# MCU_ADC0 register map
Vendor: Texas Instruments
Peripheral module from a debugger description file (folder am65x).
Registers are 32-bit, access per field, reset values left out (the file's numbers can be read two ways) unless marked. A register's access mark holds for its fields unless they carry their own. Offsets are as the file gives them; lines under a group give offsets from that group; [hi:lo] are bit positions; {n}, {i} and the like mark numbered series; 'fields as' and 'values as' point back to an identical list; <NAME> marks a mode.

## MCU_ADC0
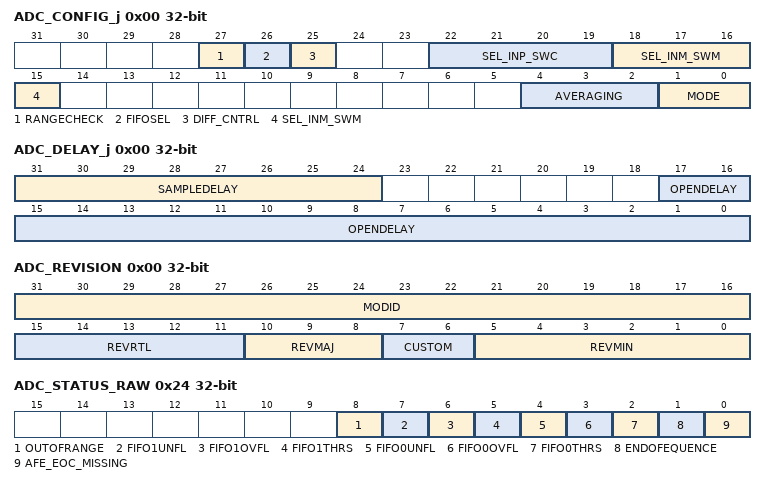
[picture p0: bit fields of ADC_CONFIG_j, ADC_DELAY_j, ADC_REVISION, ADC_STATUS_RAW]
0x00 ADC_CONFIG_j — The user should write to this register the values of the input pins send to the AFE during step 1. the StepConfig WriteEnable bit should be set to 1 before a write can occur. Offset = 64h + (j * 8h); where j = 0h to Fh
  [27] RANGECHECK rw — 0h = Disable ADC_RANGE check 1h = compare ADC data with ADC_RANGE
  [26] FIFOSEL rw — Sampled data will be stored in FIFO. 0h = FIFO0 1h = FIFO1
  [25] DIFF_CNTRL rw — DifferentialADC_CONTROL. 0h = Single ended 1h = Differential input
  [22:19] SEL_INP_SWC rw — SEL_INP pins SW configuration. 0h = Channel 1 1h = Channel 2 2h = Channel 3 3h = Channel 4 4h = Channel 5 5h = Channel 6 6h = Channel 7 7h = Channel 8 8h = VREFN
  [18:15] SEL_INM_SWM rw — SEL_INM pins negative differential. 0h = Channel 1 1h = Channel 2 2h = Channel 3 3h = Channel 4 4h = Channel 5 5h = Channel 6 6h = Channel 7 7h = Channel 8 8h = VREFN
  [4:2] AVERAGING rw — Number of samplings to average. 0h = no average 1h = 2 samples average 2h = 4 samples average 3h = 8 samples average 4h = 16 samples average
  [1:0] MODE rw — 0h = SW enabled, one-shot 1h = SW enabled, continuous 2h = HW synchronized, one-shot 3h = HW synchronized, continuous
0x00 ADC_DELAY_j — Controls number of clock periods to sample and delay. Offset = 68h + (j × 8h); where j = 0h to Fh
  [31:24] SAMPLEDELAY rw — This register will control the number of ADC clock cycles to hold SOC high. Any value programmed here will be added to the minimum requirement of 1 clock cycle.
  [17:0] OPENDELAY rw — Program the number of ADC clock cycles to wait after applying the step configuration registers and before sending the start of ADC conversion.
0x00 ADC_REVISION ro — IP Revision Identifier (X.Y.R) Used by software to track features, bugs, and compatibility.
  [31:16] MODID — Module ID field
  [15:11] REVRTL — RTLADC_REVISION. Will vary depending on release.
  [10:8] REVMAJ — Major
  [7:6] CUSTOM
  [5:0] REVMIN — Minor
0x20 ADC_EOI — The End of Interrupt () Register allows the CPU to acknowledge completion of an interrupt by writing to the for interrupt sources. An eoi_write signal will be generated and another interrupt will be triggered if interrupt sources remain. This register will be reset one cycle after it has been written to.
  [0] LINENUMEOI wo — Software End Of Interrupt (EOI) control.
0x24 ADC_STATUS_RAW — The register allows the MCU_ADC0/1 interrupt sources to be manually set when writing a 1 to a specific bit. Write 0: No action Write 1: Set event Read 0: No event pending Read 1: Event pending
  [8] OUTOFRANGE rw — Status raw for interrupt.
  [7] FIFO1UNFL rw — Status raw for interrupt.
  [6] FIFO1OVFL rw — Status raw for interrupt.
  [5] FIFO1THRS rw — Status raw for interrupt.
  [4] FIFO0UNFL rw — Status raw for interrupt.
  [3] FIFO0OVFL rw — Status raw for interrupt.
  [2] FIFO0THRS rw — Status raw for interrupt.
  [1] ENDOFEQUENCE rw — Status raw for interrupt.
  [0] AFE_EOC_MISSING rw — EOC from the analog front end missing at expected time after SOC.
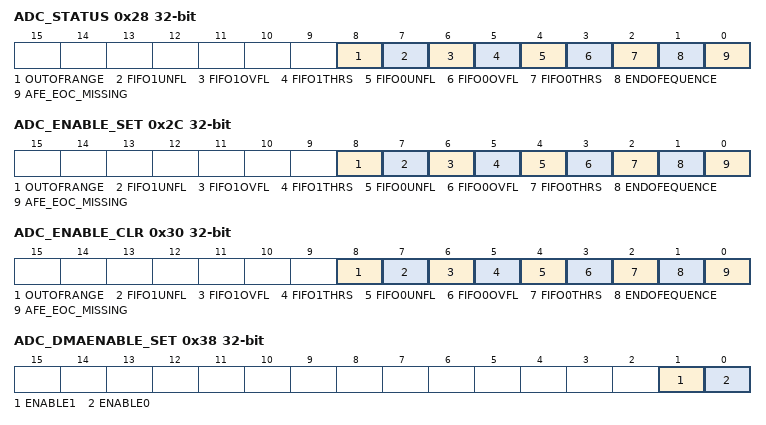
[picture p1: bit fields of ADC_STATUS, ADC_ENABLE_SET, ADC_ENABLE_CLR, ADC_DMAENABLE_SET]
0x28 ADC_STATUS — The register allows the MCU_ADC0/1 interrupt sources to be manually cleared when writing a 1 to a specific bit. Write 0: No action Write 1: Clear event Read 0: No event pending Read 1: Event pending
  [8] OUTOFRANGE rw — Enabled status for interrupt.
  [7] FIFO1UNFL rw — Enabled status for interrupt.
  [6] FIFO1OVFL rw — Enabled status for interrupt.
  [5] FIFO1THRS rw — Enabled status for interrupt.
  [4] FIFO0UNFL rw — Enabled status for interrupt.
  [3] FIFO0OVFL rw — Enabled status for interrupt.
  [2] FIFO0THRS rw — Enabled status for interrupt.
  [1] ENDOFEQUENCE rw — Enabled status for interrupt.
  [0] AFE_EOC_MISSING rw — EOC from the analog front end missing at expected time after SOC.
0x2C ADC_ENABLE_SET — The register allows the MCU_ADC0/1 interrupt sources to be manually enabled when writing a 1 to a specific bit. Write 0: No action Write 1: Enable event Read 0: Event is disabled Read 1: Event is enabled
  [8] OUTOFRANGE rw — Interrupt enable.
  [7] FIFO1UNFL rw — Interrupt enable.
  [6] FIFO1OVFL rw — Interrupt enable.
  [5] FIFO1THRS rw — Interrupt enable.
  [4] FIFO0UNFL rw — Interrupt enable.
  [3] FIFO0OVFL rw — Interrupt enable.
  [2] FIFO0THRS rw — Interrupt enable.
  [1] ENDOFEQUENCE rw — Interrupt enable.
  [0] AFE_EOC_MISSING rw — EOC from the analog front end missing at expected time after SOC
0x30 ADC_ENABLE_CLR — The register allows the MCU_ADC0/1 interrupt sources to be manually disabled when writing a 1 to a specific bit. Write 0: No action Write 1: Disable event Read 0: Event is disabled Read 1: Event is enabled
  [8] OUTOFRANGE rw — Interrupt disable.
  [7] FIFO1UNFL rw — Interrupt disable.
  [6] FIFO1OVFL rw — Interrupt disable.
  [5] FIFO1THRS rw — Interrupt disable.
  [4] FIFO0UNFL rw — Interrupt disable.
  [3] FIFO0OVFL rw — Interrupt disable.
  [2] FIFO0THRS rw — Interrupt disable.
  [1] ENDOFEQUENCE rw — Interrupt disable.
  [0] AFE_EOC_MISSING rw — EOC from the analog front end missing at expected time after SOC
0x38 ADC_DMAENABLE_SET — The register allows the enabling of DMA requests.
  [1] ENABLE1 rw — Enable DMA request FIFO1
  [0] ENABLE0 rw — Enable DMA request FIFO0
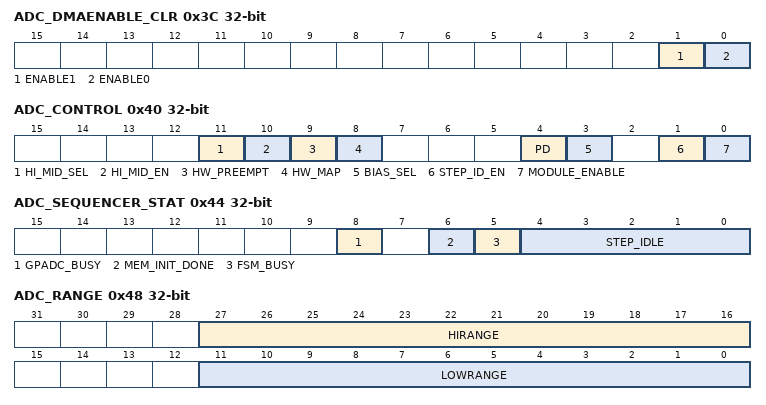
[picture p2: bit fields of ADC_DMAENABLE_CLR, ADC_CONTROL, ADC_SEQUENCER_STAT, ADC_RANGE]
0x3C ADC_DMAENABLE_CLR — The register allows the disabling of DMA requests.
  [1] ENABLE1 rw — Clears the enable of the DMA reguest FIFO1. Disable DMA request FIFO1 Write 0h = No action Write 1h = Disable DMA line Read 0h = DMA line disabled Read 1h = DMA line enabled
  [0] ENABLE0 rw — Clears the enable of the DMA reguest FIFO0. Disable DMA request FIFO0 Write 0h = No action Write 1h = Disable DMA line Read 0h = DMA line disabled Read 1h = DMA line enabled
0x40 ADC_CONTROL — Controls various parameters of the cotroller state.
  [11] HI_MID_SEL rw — Functional safety debug mode. 0h = Choose ADCREFP 1h = VMID reference input to ADC
  [10] HI_MID_EN rw — Functional safety debug mode. Enable fixed reference to ADC for testing.
  [9] HW_PREEMPT rw — 0h = SW steps are not preempted by HW events 1h = SW steps are preempted by HW events
  [8] HW_MAP rw — 0h = HW events are disabled 1h = HW events are enabled
  [4] PD rw — ADC Power Down control. 0h = AFE is powered up 1h = AFE is powered down (default) At default, AFE is powered down; Software must write 0 to turn on the power and wait 4 us before starting a conversion
  [3] BIAS_SEL rw — AFE select bias
  [1] STEP_ID_EN rw — Writing 1 to this bit will store the Step ID number with the captured ADC data in the FIFO. 0h = Write zeros 1h = Store the channel id tag
  [0] MODULE_ENABLE rw — ADC module enable bit. After programming all the configuration and step enable registers, write a 1 to this bit to start conversion. Writing a 0 will disable the module after the current conversion. Before turning on again, the ADC_SEQUENCER_STAT register show read back STEP_IDLE = 0h and FSM_BUSY = 0h. Enabling the controller will be held off until MEM_INIT_DONE = 1h.
0x44 ADC_SEQUENCER_STAT ro — SW can read this register to find out the currently scheduled step id being converted on the ADC port. If you want to turn the controller off and then back on, the step_id bit should be checked and compared to IDLE before enabling the ADC module again. Also, before enabling the controller again, the user should wait for the FSM bit 5 to read idl.
  [8] GPADC_BUSY — Monitor the AFE internal calibration (busy bit)
  [6] MEM_INIT_DONE — ADC_STATUS of RAM initialization. 1h = RAM initialization to 0 after reset is done.
  [5] FSM_BUSY — ADC_STATUS of FSM. 0h = Idle 1h = Conversion in progress
  [4:0] STEP_IDLE — 10h = Idle 0h - Fh = Corresponds to Step 1 - Step 16
0x48 ADC_RANGE — This feature requires the check interrupt bit to be enabled first. The user can decide which channel input is compared by programming the RangeCheck bit of the StepConfig Registers. It is up to software to sort through FIFO data to determine which channel data was out of . Software should only use LSB 10 bits for comparison and make sure bits 11,12 are 0.
  [27:16] HIRANGE rw — Sampled ADC data is compared to this value. If the sampled data is &gt; HIRANGE, then interrupt is generated.
  [11:0] LOWRANGE rw — Sampled ADC data is compared to this value. If the sampled data is &lt; LOWRANGE, then interrupt is generated.
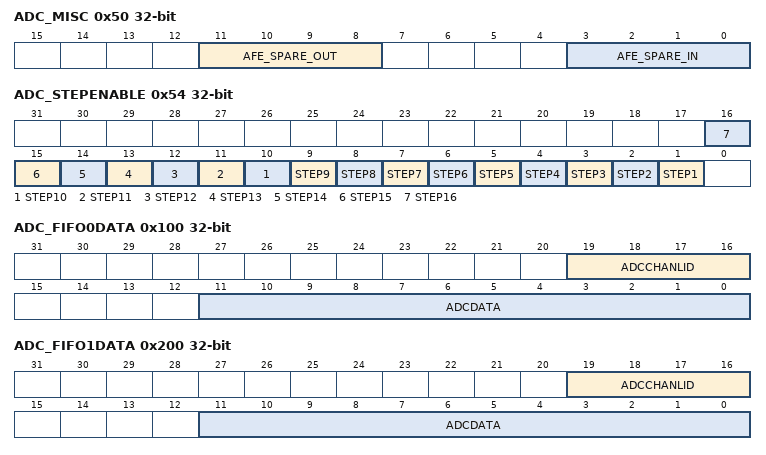
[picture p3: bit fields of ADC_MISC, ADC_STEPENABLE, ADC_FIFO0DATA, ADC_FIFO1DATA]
0x50 ADC_MISC — Spare inputs of the AFE are driven by this register, spare outputs from the AFE are read.
  [11:8] AFE_SPARE_OUT ro — Connected to AFE Spare Output pins.
  [3:0] AFE_SPARE_IN rw — Connected to AFE Spare Input pins.
0x54 ADC_STEPENABLE — Contains the enable bit for each step in the sequencer. When all steps are disabled, the FSM will stay in IDLE state. These bits can be enabled or disabled dynamically during operation. When a write to this register occurs during operational mode, the HW will make sure the new settings are updated after the END_OF_SEQUENCE event
  [n] STEP{n} rw (n=1..16) — Enable step {n}
0xE4 ADC_FIFO0WC ro — FIFO word count
  [8:0] NUMWDS — Number of words currently in the FIFO0.
0xE8 ADC_FIFO0THRESHOLD — FIFO threshold
  [7:0] THRESHOLD rw — Program the desired FIFO0 data sample level minus 1 to reach before generating interrupt to CPU.
0xEC ADC_FIFO0DMAREQ — dma request.
  [7:0] DMAREQLEVEL rw — Number of words in FIFO0 before generating a DMA request.
0xF0 ADC_FIFO1WC ro — FIFO word count
  [8:0] NUMWDS — Number of words currently in the FIFO1.
0xF4 ADC_FIFO1THRESHOLD — FIFO threshold
  [7:0] THRESHOLD rw — Program the desired FIFO1 data sample level minus 1 to reach before generating interrupt to CPU.
0xF8 ADC_FIFO1DMAREQ — dma request.
  [7:0] DMAREQLEVEL rw — Number of words in FIFO1 before generating a DMA request.
0x100 ADC_FIFO0DATA ro — A read from this register will auto increment the FIFO read pointer. If you read when FIFO is empty, it will trigger an underflow interrupt.
  [19:16] ADCCHANLID — Optional ID tag of channel that captured the data. If tag option is disabled, these bits will be 0.
  [11:0] ADCDATA — Sampled ADC converted data value stored in FIFO0.
0x200 ADC_FIFO1DATA ro — A read from this register will auto increment the FIFO read pointer. If you read when FIFO is empty, it will trigger an underflow interrupt.
  [19:16] ADCCHANLID — Optional ID tag of channel that captured the data. If tag option is disabled, these bits will be 0.
  [11:0] ADCDATA — Sampled ADC converted data value stored in FIFO1.
